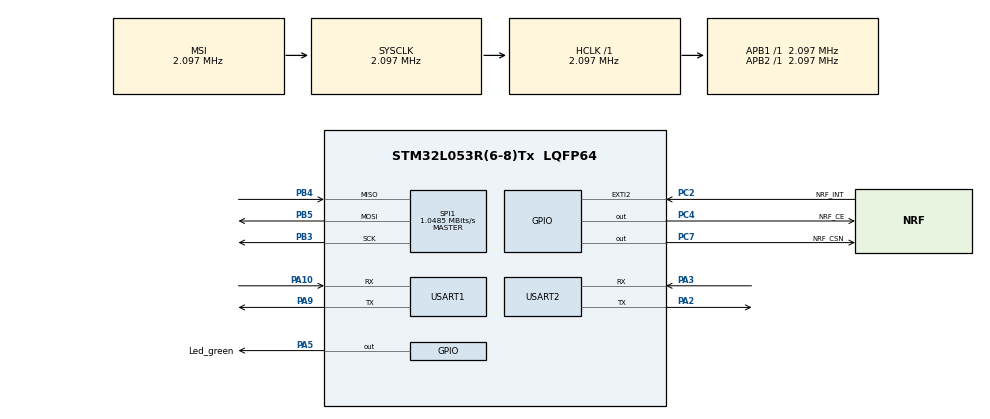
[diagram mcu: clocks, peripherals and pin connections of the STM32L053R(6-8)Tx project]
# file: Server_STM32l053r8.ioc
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Mcu.Family=STM32L0
Mcu.Name=STM32L053R(6-8)Tx
Mcu.Package=LQFP64
NVIC.EXTI2_3_IRQn=true\:0\:0\:false\:false\:true\:true\:true\:true
PA10.Mode=Asynchronous
PA10.Signal=USART1_RX
PA13.Mode=Serial_Wire
PA13.Signal=SYS_SWDIO
PA14.Mode=Serial_Wire
PA14.Signal=SYS_SWCLK
PA2.Mode=Asynchronous
PA2.Signal=USART2_TX
PA3.Mode=Asynchronous
PA3.Signal=USART2_RX
PA5.GPIO_Label=Led_green
PA5.Signal=GPIO_Output
PA9.Mode=Asynchronous
PA9.Signal=USART1_TX
PB3.Mode=Full_Duplex_Master
PB3.Signal=SPI1_SCK
PB4.Mode=Full_Duplex_Master
PB4.Signal=SPI1_MISO
PB5.Mode=Full_Duplex_Master
PB5.Signal=SPI1_MOSI
PC2.GPIO_Label=NRF_INT
PC2.GPIO_ModeDefaultEXTI=GPIO_MODE_IT_FALLING
PC2.Signal=GPXTI2
PC4.GPIO_Label=NRF_CE
PC4.GPIO_Speed=GPIO_SPEED_FREQ_HIGH
PC4.Signal=GPIO_Output
PC7.GPIO_Label=NRF_CSN
PC7.GPIO_Speed=GPIO_SPEED_FREQ_HIGH
PC7.PinState=GPIO_PIN_SET
PC7.Signal=GPIO_Output
PH0-OSC_IN.Mode=HSE-External-Oscillator
PH0-OSC_IN.Signal=RCC_OSC_IN
PH1-OSC_OUT.Mode=HSE-External-Oscillator
PH1-OSC_OUT.Signal=RCC_OSC_OUT
ProjectManager.HeapSize=0x200
ProjectManager.StackSize=0x400
ProjectManager.TargetToolchain=STM32CubeIDE
RCC.AHBFreq_Value=2097000
RCC.APB1Freq_Value=2097000
RCC.APB1TimFreq_Value=2097000
RCC.APB2Freq_Value=2097000
RCC.APB2TimFreq_Value=2097000
RCC.HSE_VALUE=8000000
RCC.HSI16_VALUE=16000000
RCC.HSI48_VALUE=48000000
RCC.HSI_VALUE=16000000
RCC.LSE_VALUE=32768
RCC.MSI_VALUE=2097000
RCC.SYSCLKFreq_VALUE=2097000
RCC.VCOOutputFreq_Value=48000000
SPI1.CalculateBaudRate=1.0485 MBits/s
SPI1.Direction=SPI_DIRECTION_2LINES
SPI1.Mode=SPI_MODE_MASTER
SPI1.VirtualType=VM_MASTER
USART1.VirtualMode-Asynchronous=VM_ASYNC
USART2.VirtualMode-Asynchronous=VM_ASYNC
board=custom

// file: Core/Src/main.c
/* USER CODE BEGIN Header */
/**
  ******************************************************************************
  * @file           : main.c
  * @brief          : Main program body
  ******************************************************************************
  * @attention
  *
  * Copyright (c) 2024 STMicroelectronics.
  * All rights reserved.
  *
  * This software is licensed under terms that can be found in the LICENSE file
  * in the root directory of this software component.
  * If no LICENSE file comes with this software, it is provided AS-IS.
  *
  ******************************************************************************
  */
/* USER CODE END Header */
#include "main.h"

/* USER CODE BEGIN Includes */
#include "Operation.h"
#define NRF_IRQ_PIN_PORT GPIOC
#define NRF_IRQ_PIN GPIO_PIN_2  // Adjusted to PC2 for the interrupt pin
/* USER CODE END Includes */

SPI_HandleTypeDef hspi1;

UART_HandleTypeDef huart1;
UART_HandleTypeDef huart2;

void SystemClock_Config(void);
static void MX_GPIO_Init(void);
static void MX_SPI1_Init(void);
static void MX_USART1_UART_Init(void);
static void MX_USART2_UART_Init(void);

/* USER CODE BEGIN 0 */
Operation opt;
/* USER CODE END 0 */

int main(void)
{

  /* MCU Configuration--------------------------------------------------------*/

  /* Reset of all peripherals, Initializes the Flash interface and the Systick. */
  HAL_Init();

  /* Configure the system clock */
  SystemClock_Config();

  /* Initialize all configured peripherals */
  MX_GPIO_Init();
  MX_SPI1_Init();
  MX_USART1_UART_Init();
  MX_USART2_UART_Init();

  /* Infinite loop */
  /* USER CODE BEGIN WHILE */
  setup(&opt);
  while (1)
  {
    if(loop(&opt))
      break;
  /* USER CODE END WHILE */

  }
}

void SystemClock_Config(void)
{
  RCC_OscInitTypeDef RCC_OscInitStruct = {0};
  RCC_ClkInitTypeDef RCC_ClkInitStruct = {0};
  RCC_PeriphCLKInitTypeDef PeriphClkInit = {0};

  /** Configure the main internal regulator output voltage
  */
  __HAL_PWR_VOLTAGESCALING_CONFIG(PWR_REGULATOR_VOLTAGE_SCALE1);

  /** Initializes the RCC Oscillators according to the specified parameters
  * in the RCC_OscInitTypeDef structure.
  */
  RCC_OscInitStruct.OscillatorType = RCC_OSCILLATORTYPE_MSI;
  RCC_OscInitStruct.MSIState = RCC_MSI_ON;
  RCC_OscInitStruct.MSICalibrationValue = 0;
  RCC_OscInitStruct.MSIClockRange = RCC_MSIRANGE_5;
  RCC_OscInitStruct.PLL.PLLState = RCC_PLL_NONE;
  if (HAL_RCC_OscConfig(&RCC_OscInitStruct) != HAL_OK)
  {
    Error_Handler();
  }

  /** Initializes the CPU, AHB and APB buses clocks
  */
  RCC_ClkInitStruct.ClockType = RCC_CLOCKTYPE_HCLK|RCC_CLOCKTYPE_SYSCLK
                              |RCC_CLOCKTYPE_PCLK1|RCC_CLOCKTYPE_PCLK2;
  RCC_ClkInitStruct.SYSCLKSource = RCC_SYSCLKSOURCE_MSI;
  RCC_ClkInitStruct.AHBCLKDivider = RCC_SYSCLK_DIV1;
  RCC_ClkInitStruct.APB1CLKDivider = RCC_HCLK_DIV1;
  RCC_ClkInitStruct.APB2CLKDivider = RCC_HCLK_DIV1;

  if (HAL_RCC_ClockConfig(&RCC_ClkInitStruct, FLASH_LATENCY_0) != HAL_OK)
  {
    Error_Handler();
  }
  PeriphClkInit.PeriphClockSelection = RCC_PERIPHCLK_USART1|RCC_PERIPHCLK_USART2;
  PeriphClkInit.Usart1ClockSelection = RCC_USART1CLKSOURCE_PCLK2;
  PeriphClkInit.Usart2ClockSelection = RCC_USART2CLKSOURCE_PCLK1;
  if (HAL_RCCEx_PeriphCLKConfig(&PeriphClkInit) != HAL_OK)
  {
    Error_Handler();
  }
}

static void MX_SPI1_Init(void)
{

  /* SPI1 parameter configuration*/
  hspi1.Instance = SPI1;
  hspi1.Init.Mode = SPI_MODE_MASTER;
  hspi1.Init.Direction = SPI_DIRECTION_2LINES;
  hspi1.Init.DataSize = SPI_DATASIZE_8BIT;
  hspi1.Init.CLKPolarity = SPI_POLARITY_LOW;
  hspi1.Init.CLKPhase = SPI_PHASE_1EDGE;
  hspi1.Init.NSS = SPI_NSS_SOFT;
  hspi1.Init.BaudRatePrescaler = SPI_BAUDRATEPRESCALER_2;
  hspi1.Init.FirstBit = SPI_FIRSTBIT_MSB;
  hspi1.Init.TIMode = SPI_TIMODE_DISABLE;
  hspi1.Init.CRCCalculation = SPI_CRCCALCULATION_DISABLE;
  hspi1.Init.CRCPolynomial = 7;
  if (HAL_SPI_Init(&hspi1) != HAL_OK)
  {
    Error_Handler();
  }

}

static void MX_USART1_UART_Init(void)
{

  huart1.Instance = USART1;
  huart1.Init.BaudRate = 115200;
  huart1.Init.WordLength = UART_WORDLENGTH_8B;
  huart1.Init.StopBits = UART_STOPBITS_1;
  huart1.Init.Parity = UART_PARITY_NONE;
  huart1.Init.Mode = UART_MODE_TX_RX;
  huart1.Init.HwFlowCtl = UART_HWCONTROL_NONE;
  huart1.Init.OverSampling = UART_OVERSAMPLING_16;
  huart1.Init.OneBitSampling = UART_ONE_BIT_SAMPLE_DISABLE;
  huart1.AdvancedInit.AdvFeatureInit = UART_ADVFEATURE_NO_INIT;
  if (HAL_UART_Init(&huart1) != HAL_OK)
  {
    Error_Handler();
  }

}

static void MX_USART2_UART_Init(void)
{

  huart2.Instance = USART2;
  huart2.Init.BaudRate = 115200;
  huart2.Init.WordLength = UART_WORDLENGTH_8B;
  huart2.Init.StopBits = UART_STOPBITS_1;
  huart2.Init.Parity = UART_PARITY_NONE;
  huart2.Init.Mode = UART_MODE_TX_RX;
  huart2.Init.HwFlowCtl = UART_HWCONTROL_NONE;
  huart2.Init.OverSampling = UART_OVERSAMPLING_16;
  huart2.Init.OneBitSampling = UART_ONE_BIT_SAMPLE_DISABLE;
  huart2.AdvancedInit.AdvFeatureInit = UART_ADVFEATURE_NO_INIT;
  if (HAL_UART_Init(&huart2) != HAL_OK)
  {
    Error_Handler();
  }

}

static void MX_GPIO_Init(void)
{
  GPIO_InitTypeDef GPIO_InitStruct = {0};

  /* GPIO Ports Clock Enable */
  __HAL_RCC_GPIOH_CLK_ENABLE();
  __HAL_RCC_GPIOC_CLK_ENABLE();
  __HAL_RCC_GPIOA_CLK_ENABLE();
  __HAL_RCC_GPIOB_CLK_ENABLE();

  /*Configure GPIO pin Output Level */
  HAL_GPIO_WritePin(Led_green_GPIO_Port, Led_green_Pin, GPIO_PIN_RESET);

  /*Configure GPIO pin Output Level */
  HAL_GPIO_WritePin(NRF_CE_GPIO_Port, NRF_CE_Pin, GPIO_PIN_RESET);

  /*Configure GPIO pin Output Level */
  HAL_GPIO_WritePin(NRF_CSN_GPIO_Port, NRF_CSN_Pin, GPIO_PIN_SET);

  /*Configure GPIO pin : NRF_INT_Pin */
  GPIO_InitStruct.Pin = NRF_INT_Pin;
  GPIO_InitStruct.Mode = GPIO_MODE_IT_FALLING;
  GPIO_InitStruct.Pull = GPIO_NOPULL;
  HAL_GPIO_Init(NRF_INT_GPIO_Port, &GPIO_InitStruct);

  /*Configure GPIO pin : Led_green_Pin */
  GPIO_InitStruct.Pin = Led_green_Pin;
  GPIO_InitStruct.Mode = GPIO_MODE_OUTPUT_PP;
  GPIO_InitStruct.Pull = GPIO_NOPULL;
  GPIO_InitStruct.Speed = GPIO_SPEED_FREQ_LOW;
  HAL_GPIO_Init(Led_green_GPIO_Port, &GPIO_InitStruct);

  /*Configure GPIO pins : NRF_CE_Pin NRF_CSN_Pin */
  GPIO_InitStruct.Pin = NRF_CE_Pin|NRF_CSN_Pin;
  GPIO_InitStruct.Mode = GPIO_MODE_OUTPUT_PP;
  GPIO_InitStruct.Pull = GPIO_NOPULL;
  GPIO_InitStruct.Speed = GPIO_SPEED_FREQ_HIGH;
  HAL_GPIO_Init(GPIOC, &GPIO_InitStruct);

  /* EXTI interrupt init*/
  HAL_NVIC_SetPriority(EXTI2_3_IRQn, 0, 0);
  HAL_NVIC_EnableIRQ(EXTI2_3_IRQn);

}

/* USER CODE BEGIN 4 */
// Interrupt callback for handling NRF24L01+ TX/RX interrupts
void HAL_GPIO_EXTI_Callback(uint16_t GPIO_Pin)
{
	if (GPIO_Pin == NRF_IRQ_PIN)
  {
		Rx_Tx_Callback_Handler(&opt);
  }
}
/* USER CODE END 4 */

void Error_Handler(void)
{
  __disable_irq();
  while (1)
  {
  }
}
